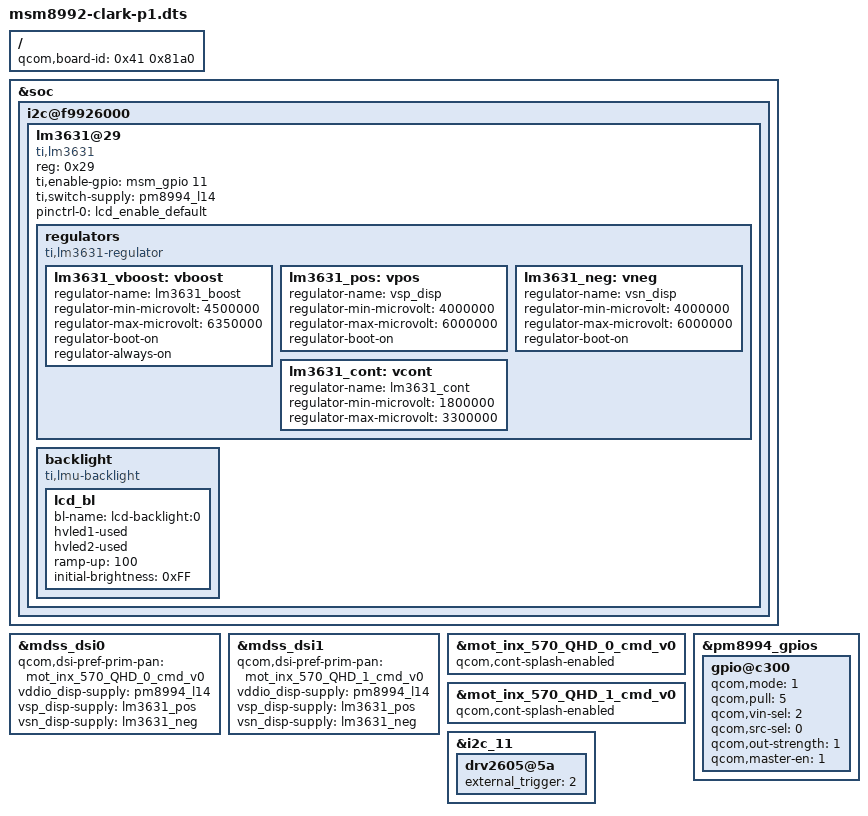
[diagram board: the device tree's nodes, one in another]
/* Copyright (c) 2015, Motorola Mobility LLC. All rights reserved.
 *
 * This program is free software; you can redistribute it and/or modify
 * it under the terms of the GNU General Public License version 2 and
 * only version 2 as published by the Free Software Foundation.
 *
 * This program is distributed in the hope that it will be useful,
 * but WITHOUT ANY WARRANTY; without even the implied warranty of
 * MERCHANTABILITY or FITNESS FOR A PARTICULAR PURPOSE.  See the
 * GNU General Public License for more details.
 */


/dts-v1/;

#include "msm8992-clark.dtsi"
#include "dsi-panel-mot-inx-570-QHD-cmd.dtsi"

/ {
	qcom,board-id = <0x41 0x81a0>;
};

&soc {
	/delete-node/ isl98611a_pos;
	/delete-node/ isl98611a_neg;
	i2c@f9926000 { /* BLSP1 QUP3 */
		/delete-node/ isl98611@29;

		lm3631@29 {
			compatible = "ti,lm3631";
			reg = <0x29>;
			status = "okay";
			ti,enable-gpio = <&msm_gpio 11 0>;
			ti,switch-supply = "pm8994_l14";

			pinctrl-names = "default";
			pinctrl-0 = <&lcd_enable_default>;

			/* Only Vpos and Vneg are used with LCD boost */
			regulators {
				compatible = "ti,lm3631-regulator";

				lm3631_vboost: vboost {
					regulator-name = "lm3631_boost";
					regulator-min-microvolt = <4500000>;
					regulator-max-microvolt = <6350000>;
					regulator-boot-on;
					regulator-always-on;
				};

				lm3631_pos: vpos {
					regulator-name = "vsp_disp";
					regulator-min-microvolt = <4000000>;
					regulator-max-microvolt = <6000000>;
					regulator-boot-on;
				};

				lm3631_neg: vneg {
					regulator-name = "vsn_disp";
					regulator-min-microvolt = <4000000>;
					regulator-max-microvolt = <6000000>;
					regulator-boot-on;
				};

				lm3631_cont: vcont {
					regulator-name = "lm3631_cont";
					regulator-min-microvolt = <1800000>;
					regulator-max-microvolt = <3300000>;
				};
			};

			backlight {
				compatible = "ti,lmu-backlight", "ti,lm3631-backlight";

				lcd_bl {
					bl-name = "lcd-backlight:0";
					hvled1-used;
					hvled2-used;
					ramp-up = <100>;
					initial-brightness = /bits/ 8 <0xFF>;
				};
			};
		};
	};
};

&mdss_dsi0 {
	qcom,dsi-pref-prim-pan = <&mot_inx_570_QHD_0_cmd_v0>;
	vddio_disp-supply = <&pm8994_l14>;
	vsp_disp-supply = <&lm3631_pos>;
	vsn_disp-supply = <&lm3631_neg>;

	/delete-node/ qcom,panel-supply-entries;
	#include"dsi-panel-mot-inx-570-QHD-supplies.dtsi"
};

&mdss_dsi1 {
	qcom,dsi-pref-prim-pan = <&mot_inx_570_QHD_1_cmd_v0>;
	vddio_disp-supply = <&pm8994_l14>;
	vsp_disp-supply = <&lm3631_pos>;
	vsn_disp-supply = <&lm3631_neg>;

	/delete-node/ qcom,panel-supply-entries;
	#include"dsi-panel-mot-inx-570-QHD-supplies.dtsi"
};

&mot_inx_570_QHD_0_cmd_v0 {
	qcom,cont-splash-enabled;
};

&mot_inx_570_QHD_1_cmd_v0 {
	qcom,cont-splash-enabled;
};

&pm8994_gpios {
	gpio@c300 { /* GPIO 4 - EN_BST_BYP */
		status = "okay";
		qcom,mode = <1>; /* Output */
		qcom,pull = <5>; /* None */
		qcom,vin-sel = <2>;
		qcom,src-sel = <0>;
		qcom,out-strength = <1>;
		qcom,master-en = <1>;
	};
};

&i2c_11 {
	drv2605@5a {
		external_trigger = <2>; /* Disable ext. trigger */
	};
};
